# CY8C5888LTQ_LP097 register map
File version: 0.1
Registers are 8-bit, read-write, no defined reset value unless marked. A register's access mark holds for its fields unless they carry their own. Offsets are from the block's base; [hi:lo] are bit positions; 'fields as' and 'values as' point back to an identical list.

## UART_LOG — UART
Base 0x00000000
0x40006429 RX_UART_LOG_RX_ADDRESS1 — RX Address1 Register
0x40006439 RX_UART_LOG_RX_ADDRESS2 — RX Address2 Register
0x40006449 RX_UART_LOG_RX_DATA — RX Data Register
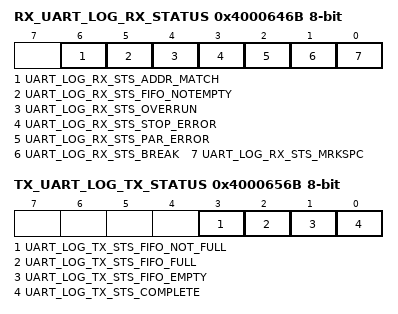
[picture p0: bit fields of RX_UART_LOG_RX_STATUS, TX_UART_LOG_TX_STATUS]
0x4000646B RX_UART_LOG_RX_STATUS — RX status register
  [6] UART_LOG_RX_STS_ADDR_MATCH ro, [5] UART_LOG_RX_STS_FIFO_NOTEMPTY ro, [4] UART_LOG_RX_STS_OVERRUN ro, [3] UART_LOG_RX_STS_STOP_ERROR ro, [2] UART_LOG_RX_STS_PAR_ERROR ro, [1] UART_LOG_RX_STS_BREAK ro, [0] UART_LOG_RX_STS_MRKSPC ro
0x4000654B TX_UART_LOG_TX_DATA — TX Data Register
0x4000656B TX_UART_LOG_TX_STATUS — TX status register
  [3] UART_LOG_TX_STS_FIFO_NOT_FULL ro, [2] UART_LOG_TX_STS_FIFO_FULL ro, [1] UART_LOG_TX_STS_FIFO_EMPTY ro, [0] UART_LOG_TX_STS_COMPLETE ro

## LED_PWM_YELLOW
Base 0x00000000
0x4000642A LED_PWM_YELLOW_COMPARE_Reg 16-bit — UDB.D0 - Assigned Compare Value
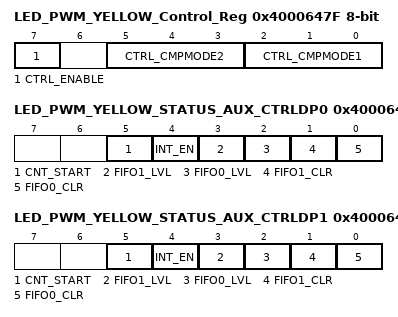
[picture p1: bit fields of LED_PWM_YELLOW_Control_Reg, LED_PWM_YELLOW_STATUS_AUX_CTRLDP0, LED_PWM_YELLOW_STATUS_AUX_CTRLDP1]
0x4000647F LED_PWM_YELLOW_Control_Reg — UDB Control Register - Assigned Control Register Value
  [7] CTRL_ENABLE — Enable the PWM
  [5:3] CTRL_CMPMODE2 — Compare mode 2
  [2:0] CTRL_CMPMODE1 — Compare mode 1
0x4000649A LED_PWM_YELLOW_STATUS_AUX_CTRLDP0 — UDB Auxilliary Control Register
  [5] CNT_START — FIFO0 clear
    0=E_CNT_START0 (Disable counter); 1=E_CNT_START1 (Enable counter)
  [4] INT_EN
    0=E_INT_EN0 (Interrupt disabled); 1=E_INT_EN1 (Interrupt enabled)
  [3] FIFO1_LVL — FIFO level
    0=E_FIFO_LVL_0 (FIFO LVL: input mode: FIFO not full; output mode: FIFO not empty); 1=E_FIFO_LVL_1 (FIFO LVL: input mode: FIFO at least 1/2 empty; output mode: FIFO at least 1/2 full)
  [2] FIFO0_LVL — FIFO level
    values as FIFO1_LVL
  [1] FIFO1_CLR — FIFO1 clear
    0=E_FIFO_CLR_0 (Normal FIFO operation); 1=E_FIFO_CLR_1 (Clear FIFO state)
  [0] FIFO0_CLR — FIFO0 clear
    values as FIFO1_CLR
0x4000649B LED_PWM_YELLOW_STATUS_AUX_CTRLDP1 — UDB Auxilliary Control Register
  fields as LED_PWM_YELLOW_STATUS_AUX_CTRLDP0

## LED_PWM_GREEN
Base 0x00000000
0x40006422 LED_PWM_GREEN_COMPARE_Reg 16-bit — UDB.D0 - Assigned Compare Value
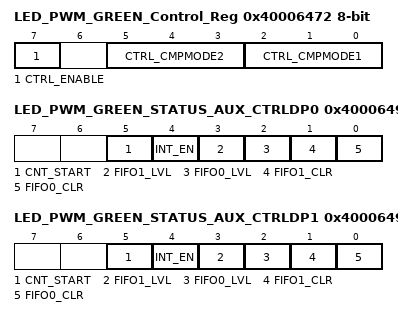
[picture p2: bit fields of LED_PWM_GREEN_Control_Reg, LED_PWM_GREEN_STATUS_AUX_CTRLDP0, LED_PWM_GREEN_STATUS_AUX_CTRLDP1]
0x40006472 LED_PWM_GREEN_Control_Reg — UDB Control Register - Assigned Control Register Value
  [7] CTRL_ENABLE — Enable the PWM
  [5:3] CTRL_CMPMODE2 — Compare mode 2
  [2:0] CTRL_CMPMODE1 — Compare mode 1
0x40006492 LED_PWM_GREEN_STATUS_AUX_CTRLDP0 — UDB Auxilliary Control Register
  [5] CNT_START — FIFO0 clear
    0=E_CNT_START0 (Disable counter); 1=E_CNT_START1 (Enable counter)
  [4] INT_EN
    0=E_INT_EN0 (Interrupt disabled); 1=E_INT_EN1 (Interrupt enabled)
  [3] FIFO1_LVL — FIFO level
    0=E_FIFO_LVL_0 (FIFO LVL: input mode: FIFO not full; output mode: FIFO not empty); 1=E_FIFO_LVL_1 (FIFO LVL: input mode: FIFO at least 1/2 empty; output mode: FIFO at least 1/2 full)
  [2] FIFO0_LVL — FIFO level
    values as FIFO1_LVL
  [1] FIFO1_CLR — FIFO1 clear
    0=E_FIFO_CLR_0 (Normal FIFO operation); 1=E_FIFO_CLR_1 (Clear FIFO state)
  [0] FIFO0_CLR — FIFO0 clear
    values as FIFO1_CLR
0x40006493 LED_PWM_GREEN_STATUS_AUX_CTRLDP1 — UDB Auxilliary Control Register
  fields as LED_PWM_GREEN_STATUS_AUX_CTRLDP0

## LED_PWM_RED
Base 0x00000000
0x40006424 LED_PWM_RED_COMPARE_Reg 16-bit — UDB.D0 - Assigned Compare Value
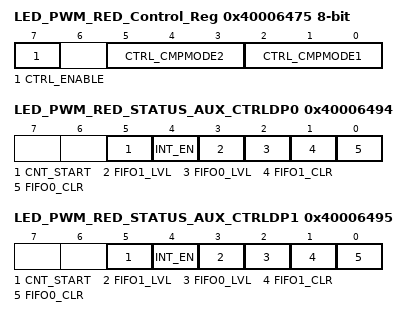
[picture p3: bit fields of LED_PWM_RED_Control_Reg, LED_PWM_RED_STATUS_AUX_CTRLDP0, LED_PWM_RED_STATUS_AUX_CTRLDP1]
0x40006475 LED_PWM_RED_Control_Reg — UDB Control Register - Assigned Control Register Value
  [7] CTRL_ENABLE — Enable the PWM
  [5:3] CTRL_CMPMODE2 — Compare mode 2
  [2:0] CTRL_CMPMODE1 — Compare mode 1
0x40006494 LED_PWM_RED_STATUS_AUX_CTRLDP0 — UDB Auxilliary Control Register
  [5] CNT_START — FIFO0 clear
    0=E_CNT_START0 (Disable counter); 1=E_CNT_START1 (Enable counter)
  [4] INT_EN
    0=E_INT_EN0 (Interrupt disabled); 1=E_INT_EN1 (Interrupt enabled)
  [3] FIFO1_LVL — FIFO level
    0=E_FIFO_LVL_0 (FIFO LVL: input mode: FIFO not full; output mode: FIFO not empty); 1=E_FIFO_LVL_1 (FIFO LVL: input mode: FIFO at least 1/2 empty; output mode: FIFO at least 1/2 full)
  [2] FIFO0_LVL — FIFO level
    values as FIFO1_LVL
  [1] FIFO1_CLR — FIFO1 clear
    0=E_FIFO_CLR_0 (Normal FIFO operation); 1=E_FIFO_CLR_1 (Clear FIFO state)
  [0] FIFO0_CLR — FIFO0 clear
    values as FIFO1_CLR
0x40006495 LED_PWM_RED_STATUS_AUX_CTRLDP1 — UDB Auxilliary Control Register
  fields as LED_PWM_RED_STATUS_AUX_CTRLDP0

## SEVEN_reg
Base 0x00000000
0x40006579 SEVEN_reg_CONTROL_REG
